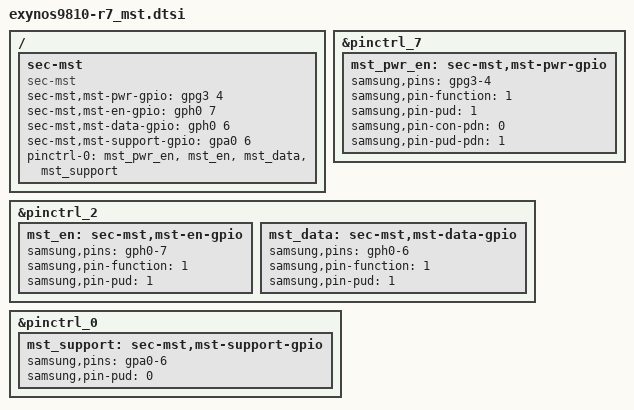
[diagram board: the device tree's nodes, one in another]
/* Copyright (c) 2013, Samsung Electronics Corporation. All rights reserved.
 *
 * This program is free software; you can redistribute it and/or modify
 * it under the terms of the GNU General Public License version 2 and
 * only version 2 as published by the Free Software Foundation.
 *
 * This program is distributed in the hope that it will be useful,
 * but WITHOUT ANY WARRANTY; without even the implied warranty of
 * MERCHANTABILITY or FITNESS FOR A PARTICULAR PURPOSE.  See the
 * GNU General Public License for more details.
 */

/ {
	fragment@model {
		target-path = "/";
		__overlay__ {
			sec-mst{
				compatible = "sec-mst";
				sec-mst,mst-pwr-gpio = <&gpg3 4 0>;
				sec-mst,mst-en-gpio = <&gph0 7 0>;
				sec-mst,mst-data-gpio = <&gph0 6 0>;
				sec-mst,mst-support-gpio = <&gpa0 6 0>;

				pinctrl-names = "default";
				pinctrl-0 = <&mst_pwr_en &mst_en &mst_data &mst_support>;
			};
		};
	};
};

//pinctrl_7: pinctrl@10830000
&pinctrl_7 {
	mst_pwr_en: sec-mst,mst-pwr-gpio {
		samsung,pins ="gpg3-4";
		samsung,pin-function = <1>;
		samsung,pin-pud = <1>;
		samsung,pin-con-pdn = <0>;
		samsung,pin-pud-pdn = <1>;
	};
};

//pinctrl_2: pinctrl@13A80000
&pinctrl_2 {
	mst_en: sec-mst,mst-en-gpio {
		samsung,pins ="gph0-7";
		samsung,pin-function = <1>;
		samsung,pin-pud = <1>;
	};

	mst_data: sec-mst,mst-data-gpio {
		samsung,pins ="gph0-6";
		samsung,pin-function = <1>;
		samsung,pin-pud = <1>;
	};
};

//pinctrl_0: pinctrl@14050000
&pinctrl_0 {
	mst_support: sec-mst,mst-support-gpio {
		samsung,pins ="gpa0-6";
		samsung,pin-pud = <0>;
	};
};


